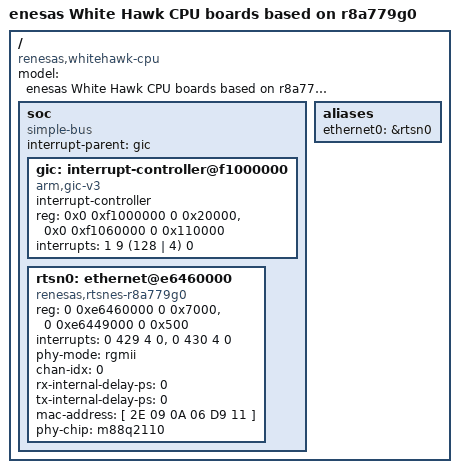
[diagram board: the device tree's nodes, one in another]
// SPDX-License-Identifier: GPL-2.0
/*
 * Device Tree Source for the White Hawk CPU boards with R-Car V4H
 *
 * Copyright (C) 2021 Renesas Electronics Corp.
 */

/dts-v1/;
/* Reserved 1MB memory for boot loader secure area */
/memreserve/ 0x50000000 0x00100000;
/ {
	compatible = "renesas,r8a779g0";
	#address-cells = <2>;
	#size-cells = <2>;


	soc: soc {
		compatible = "simple-bus";
        interrupt-parent = <&gic>;
		#address-cells = <2>;
		#size-cells = <2>;
		ranges;

		gic: interrupt-controller@f1000000 {
			compatible = "arm,gic-v3";
			#interrupt-cells = <4>;
			#address-cells = <0>;
			interrupt-controller;
			reg = <0x0 0xf1000000 0 0x20000>,
			      <0x0 0xf1060000 0 0x110000>;
			interrupts = <1 9 (128 | 4) 0>;
		};

		rtsn0: ethernet@e6460000 {
			compatible = "renesas,rtsnes-r8a779g0",
				     "renesas,rtsnes-rcar-gen4";
			reg = <0 0xe6460000 0 0x7000>, <0 0xe6449000 0 0x500>;
			interrupts = <0 429 4 0>,
                         <0 430 4 0>;
			interrupt-names = "axibmi_tx", "axibmi_rx";
			phy-mode = "rgmii";
            chan-idx = "0";
			rx-internal-delay-ps = <0>;
			tx-internal-delay-ps = <0>;
			#address-cells = <1>;
			#size-cells = <0>;
			status = "disabled";
		};
	};
};

/ {
	model = "enesas White Hawk CPU boards based on r8a779g0";
	compatible = "renesas,whitehawk-cpu", "renesas,r8a779g0";
	aliases {
		ethernet0 = &rtsn0;
	};
};

&rtsn0 {
    mac-address = [ 2E 09 0A 06 D9 11 ];
    phy-chip = "m88q2110";
    status = "okay";
};

